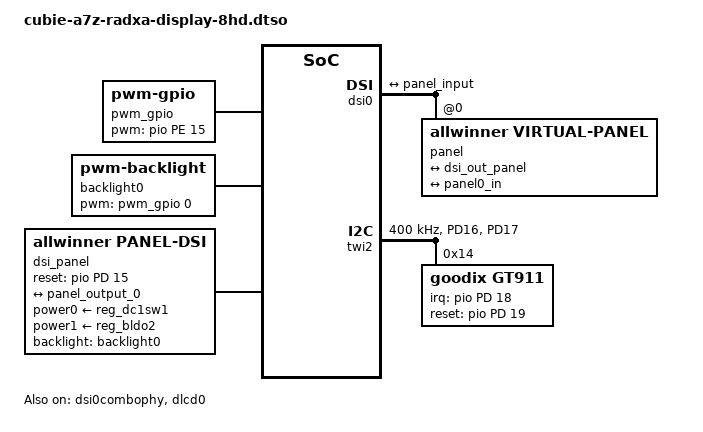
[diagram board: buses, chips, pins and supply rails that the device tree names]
/dts-v1/;
/plugin/;

#include <dt-bindings/gpio/gpio.h>
#include <dt-bindings/gpio/sun4i-gpio.h>
#include <dt-bindings/display/sunxi-lcd.h>
#include <dt-bindings/interrupt-controller/irq.h>

/ {
	metadata {
		title = "Enable Radxa Display 8HD for Cubie A7Z V2.0+";
		compatible = "radxa,cubie-a7z";
		category = "display";
		exclusive = "dlcd0", "dsi0", "dsi0combophy", "PD18", "PD19", "PD16", "PD17", "PD15", "PE15";
		description = "Enable Radxa Display 8HD for Cubie A7Z V2.0+";
	};
};

&{/} {

	pwm_gpio: pwm-gpio {
		compatible = "pwm-gpio";
		#pwm-cells = <3>;
		pwm-gpios = <&pio PE 15 GPIO_ACTIVE_HIGH>;
	};

	backlight0: backlight0 {
		compatible = "pwm-backlight";
		status = "okay";
		brightness-levels = <1 255>;
		num-interpolated-steps = <255>;
		default-brightness-level = <200>;
		pwms = <&pwm_gpio 0 25000 0>;
	};

	dsi_panel: dsi_panel@1 {
		compatible = "allwinner,panel-dsi";
		status = "okay";
		power-delay-ms = <10>;
		power0-supply = <&reg_dc1sw1>;
		power1-supply = <&reg_bldo2>;
		
		reset-num = <1>;
		reset-delay-ms = <20>;
		reset-gpios = <&pio PD 15 GPIO_ACTIVE_HIGH>;
		backlight = <&backlight0>;
		dsi,flags = <(MIPI_DSI_MODE_VIDEO)>;
		dsi,lanes = <4>;
		dsi,format = <0>;

		panel-init-sequence = [
			15 00 02 E0 00
			15 00 02 E1 93
			15 00 02 E2 65
			15 00 02 E3 F8
			15 00 02 80 03

			15 00 02 E0 01
			15 00 02 00 00
			15 00 02 01 7E
			15 00 02 03 00
			15 00 02 04 65
			15 00 02 0C 74
			15 00 02 17 00
			15 00 02 18 B7
			15 00 02 19 00
			15 00 02 1A 00
			15 00 02 1B B7
			15 00 02 1C 00
			
			15 00 02 24 FE
			15 00 02 37 19
			15 00 02 38 05
			15 00 02 39 00
			15 00 02 3A 01
			15 00 02 3B 01
			15 00 02 3C 70
			15 00 02 3D FF
			15 00 02 3E FF
			15 00 02 3F FF

			15 00 02 40 06
			15 00 02 41 A0
			15 00 02 43 1E
			15 00 02 44 0F
			15 00 02 45 28
			15 00 02 4B 04

			15 00 02 55 02
			15 00 02 56 01
			15 00 02 57 A9
			15 00 02 58 0A
			15 00 02 59 0A
			15 00 02 5A 37
			15 00 02 5B 19
			15 00 02 5D 78
			15 00 02 5E 63
			15 00 02 5F 54
			
			15 00 02 60 49
			15 00 02 61 45
			15 00 02 62 38
			15 00 02 63 3D
			15 00 02 64 28
			15 00 02 65 43
			15 00 02 66 41
			15 00 02 67 43
			15 00 02 68 62
			15 00 02 69 50
			15 00 02 6A 57
			15 00 02 6B 49
			15 00 02 6C 44
			15 00 02 6D 37
			15 00 02 6E 23
			15 00 02 6F 10
			
			15 00 02 70 78
			15 00 02 71 63
			15 00 02 72 54
			15 00 02 73 49
			15 00 02 74 45
			15 00 02 75 38
			15 00 02 76 3D
			15 00 02 77 28
			15 00 02 78 43
			15 00 02 79 41
			15 00 02 7A 43
			15 00 02 7B 62
			15 00 02 7C 50
			15 00 02 7D 57
			15 00 02 7E 49
			15 00 02 7F 44
			
			15 00 02 80 37
			15 00 02 81 23
			15 00 02 82 10

			15 00 02 E0 02
			15 00 02 00 47
			15 00 02 01 47
			15 00 02 02 45
			15 00 02 03 45
			15 00 02 04 4B
			15 00 02 05 4B
			15 00 02 06 49
			15 00 02 07 49
			15 00 02 08 41
			15 00 02 09 1F
			15 00 02 0A 1F
			15 00 02 0B 1F
			15 00 02 0C 1F
			15 00 02 0D 1F
			15 00 02 0E 1F
			15 00 02 0F 5F
			15 00 02 10 5F
			15 00 02 11 57
			15 00 02 12 77
			15 00 02 13 35
			15 00 02 14 1F
			15 00 02 15 1F

			15 00 02 16 46
			15 00 02 17 46
			15 00 02 18 44
			15 00 02 19 44
			15 00 02 1A 4A
			15 00 02 1B 4A
			15 00 02 1C 48
			15 00 02 1D 48
			15 00 02 1E 40
			15 00 02 1F 1F
			15 00 02 20 1F
			15 00 02 21 1F
			15 00 02 22 1F
			15 00 02 23 1F
			15 00 02 24 1F
			15 00 02 25 5F
			15 00 02 26 5F
			15 00 02 27 57
			15 00 02 28 77
			15 00 02 29 35
			15 00 02 2A 1F
			15 00 02 2B 1F

			15 00 02 58 40
			15 00 02 59 00
			15 00 02 5A 00
			15 00 02 5B 10
			15 00 02 5C 06
			15 00 02 5D 40
			15 00 02 5E 01
			15 00 02 5F 02
			15 00 02 60 30
			15 00 02 61 01
			15 00 02 62 02
			15 00 02 63 03
			15 00 02 64 6B
			15 00 02 65 05
			15 00 02 66 0C
			15 00 02 67 73
			15 00 02 68 09
			15 00 02 69 03
			15 00 02 5A 56
			15 00 02 6B 08
			15 00 02 6C 00
			15 00 02 6D 04
			15 00 02 6E 04
			15 00 02 6F 88
			15 00 02 70 00
			15 00 02 71 00
			15 00 02 72 06
			15 00 02 73 7B
			15 00 02 74 00
			15 00 02 75 F8
			15 00 02 76 00
			15 00 02 77 D5
			15 00 02 78 2E
			15 00 02 79 12
			15 00 02 7A 03
			15 00 02 7B 00
			15 00 02 7C 00
			15 00 02 7D 03
			15 00 02 7E 7B

			15 00 02 E0 04
			15 00 02 00 0E
			15 00 02 02 B3
			15 00 02 09 60
			15 00 02 0E 2A
			15 00 02 37 58
			15 78 02 E0 00
			05 78 01 11
			05 14 01 29
		];

		panel-exit-sequence = [
			05 00 01 28
			05 00 01 10
		];

		disp_timings0: display-timings {
			native-mode = <&dsi1_timing0>;
			dsi1_timing0: timing0 {
				clock-frequency = <70000000>;
				hback-porch = <18>;
				hactive = <800>;
				hfront-porch = <18>;
				hsync-len = <18>;
				vback-porch = <10>;
				vactive = <1280>;
				vfront-porch = <20>;
				vsync-len = <4>;
			};
		};

		port {
			panel0_in: endpoint@0 {
				reg = <0>;
				remote-endpoint = <&panel_output_0>;
			};
		};
	};
};

&dsi0combophy {
	status = "okay";
};

&dlcd0 {
	status = "okay";
};

&dsi0 {
	status = "okay";
	pinctrl-0 = <&dsi0_4lane_pins_a>;
	pinctrl-1 = <&dsi0_4lane_pins_b>;
	pinctrl-names = "active","sleep";

	ports {
		dsi0_out: port@1{
			reg = <1>;
			dsi_out_panel: endpoint {
				remote-endpoint = <&panel_input>;
			};
		};
	};
	panel: panel@0 {
		compatible = "allwinner,virtual-panel";
		status = "okay";
		reg = <0>;
		ports {
			panel_in: port@0 {
				reg = <0>;
				panel_input: endpoint@0 {
					reg = <0>;
					remote-endpoint = <&dsi_out_panel>;
				};
			};
			panel_out: port@1 {
				reg = <1>;
				panel_output_0: endpoint@0 {
					reg = <0>;
					remote-endpoint = <&panel0_in>;
				};
			};
		};
	};
};

&twi2 {
	clock-frequency = <400000>;
	pinctrl-0 = <&twi2_pins_default>;
	pinctrl-1 = <&twi2_pins_sleep>;
	pinctrl-names = "default", "sleep";
	/* For stability and backwards compatibility, we recommend setting ‘twi_drv_used’ to 1 */
	twi_drv_used = <1>;
	no_suspend = <1>;
	twi-supply = <&reg_dc1sw1>;
	status = "okay";

	gt911@14 {
		compatible = "goodix,gt911";
		reg = <0x14>;
		pinctrl-names = "default";
		interrupt-parent = <&pio>;
		interrupts = <PD 18 IRQ_TYPE_EDGE_FALLING>;
		irq-gpios = <&pio PD 18 GPIO_ACTIVE_HIGH>;
		reset-gpios = <&pio PD 19 GPIO_ACTIVE_HIGH>;
		status = "okay";
	};
};

&pio {
	twi2_pins_default: twi2@0 {
		pins = "PD16", "PD17";
		function = "twi2";
		drive-strength = <10>;
		bias-pull-up;
	};

	twi2_pins_sleep: twi2@1 {
		pins = "PD16", "PD17";
		function = "gpio_in";
	};
};
